# HC32K118 register map
File version: 1.0
CPU: CM0+ r0p1, little endian, no MPU, no FPU, 2 interrupt priority bits
Registers are 32-bit, read-write, reset 0x0 unless marked. A register's access mark holds for its fields unless they carry their own. Offsets are from the block's base; [hi:lo] are bit positions; {n}, {i} and the like mark numbered series; 'fields as' and 'values as' point back to an identical list.

## CMU
Base 0x40014400
0x00 PERICKSEL 8-bit
  [2:0] PERICKSEL
0x04 XTALSTDSR 8-bit
  [0] XTALSTDF
0x08 SCKDIVR 8-bit
  [2:0] SCKDIV
0x0C CKSWR 8-bit
  [1:0] CKSW
0x10 XTALCR 8-bit reset 0x1
  [0] XTALSTP
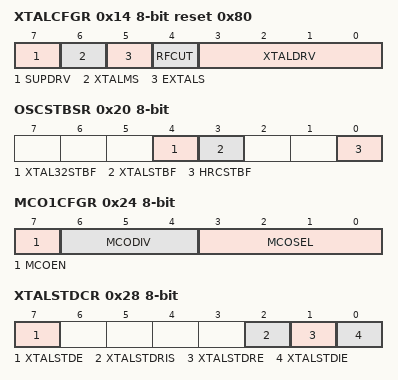
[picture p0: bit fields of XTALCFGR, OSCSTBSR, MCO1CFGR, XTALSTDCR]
0x14 XTALCFGR 8-bit reset 0x80
  [7] SUPDRV, [6] XTALMS, [5] EXTALS, [4] RFCUT, [3:0] XTALDRV
0x15 XTALSTBCR 8-bit
  [2:0] XTALSTB
0x18 HRCCR 8-bit
  [0] HRCSTP
0x20 OSCSTBSR 8-bit ro
  [4] XTAL32STBF, [3] XTALSTBF, [0] HRCSTBF
0x24 MCO1CFGR 8-bit
  [7] MCOEN, [6:4] MCODIV, [3:0] MCOSEL
0x28 XTALSTDCR 8-bit
  [7] XTALSTDE, [2] XTALSTDRIS, [1] XTALSTDRE, [0] XTALSTDIE
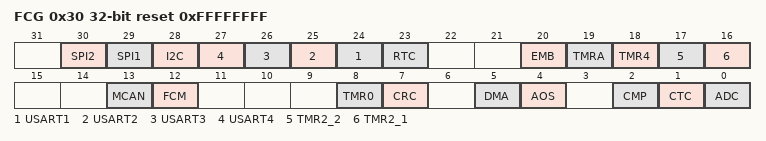
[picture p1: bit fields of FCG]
0x30 FCG reset 0xFFFFFFFF
  [30] SPI2, [29] SPI1, [28] I2C, [n+23] USART{n} (n=1..4), [23] RTC, [20] EMB, [19] TMRA, [18] TMR4, [17] TMR2_2, [16] TMR2_1, [13] MCAN, [12] FCM, [8] TMR0, [7] CRC, [5] DMA, [4] AOS, [2] CMP, [1] CTC, [0] ADC
0x34 XTAL32CR 8-bit reset 0x1
  [0] XTAL32STP
0x38 XTAL32CFGR 8-bit
  [0] XTAL32DRV
0x39 XTAL32NFR 8-bit
  [1:0] XTAL32NF
0x3C LRCCR 8-bit
  [0] LRCSTP
0x40 CANCKCFGR 8-bit
  [0] CANCKS

## CRC
Base 0x40015400
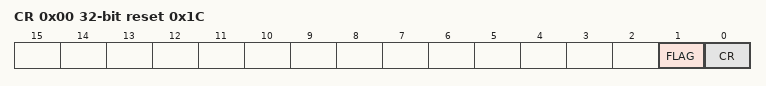
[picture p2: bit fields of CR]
0x00 CR reset 0x1C
  [1] FLAG, [0] CR
0x04 RESLT reset 0x7800
{0x80+4i} DAT{i} (i=0..31)

## CTC
Base 0x40000000
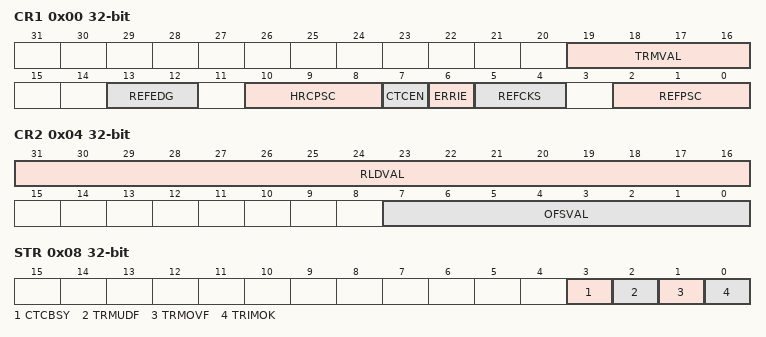
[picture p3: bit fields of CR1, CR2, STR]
0x00 CR1
  [19:16] TRMVAL, [13:12] REFEDG, [10:8] HRCPSC, [7] CTCEN, [6] ERRIE, [5:4] REFCKS, [2:0] REFPSC
0x04 CR2
  [31:16] RLDVAL, [7:0] OFSVAL
0x08 STR ro
  [3] CTCBSY, [2] TRMUDF, [1] TRMOVF, [0] TRIMOK
0x0C CNT 16-bit ro

## DBGC
Base 0x40015000
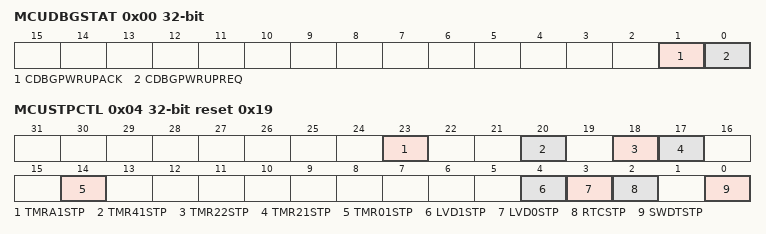
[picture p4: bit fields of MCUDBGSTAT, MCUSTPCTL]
0x00 MCUDBGSTAT
  [1] CDBGPWRUPACK, [0] CDBGPWRUPREQ
0x04 MCUSTPCTL reset 0x19
  [23] TMRA1STP, [20] TMR41STP, [18] TMR22STP, [17] TMR21STP, [14] TMR01STP, [4] LVD1STP, [3] LVD0STP, [2] RTCSTP, [0] SWDTSTP

## DBGC_T
Base 0xE0042000
{0x0+4i} AUTHID{i} (i=0..2)
0x0C CHIPID ro reset 0x58480118
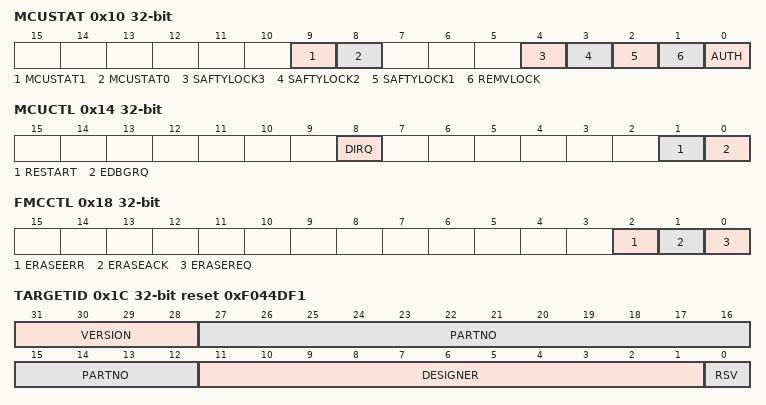
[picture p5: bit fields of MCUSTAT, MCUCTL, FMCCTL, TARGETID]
0x10 MCUSTAT
  [9] MCUSTAT1, [8] MCUSTAT0, [4] SAFTYLOCK3, [3] SAFTYLOCK2, [2] SAFTYLOCK1, [1] REMVLOCK, [0] AUTH
0x14 MCUCTL
  [8] DIRQ, [1] RESTART, [0] EDBGRQ
0x18 FMCCTL
  [2] ERASEERR, [1] ERASEACK, [0] ERASEREQ
0x1C TARGETID ro reset 0xF044DF1
  [31:28] VERSION, [27:12] PARTNO, [11:1] DESIGNER, [0] RSV

## DMA
Base 0x40013000
0x00 EN
  [0] EN
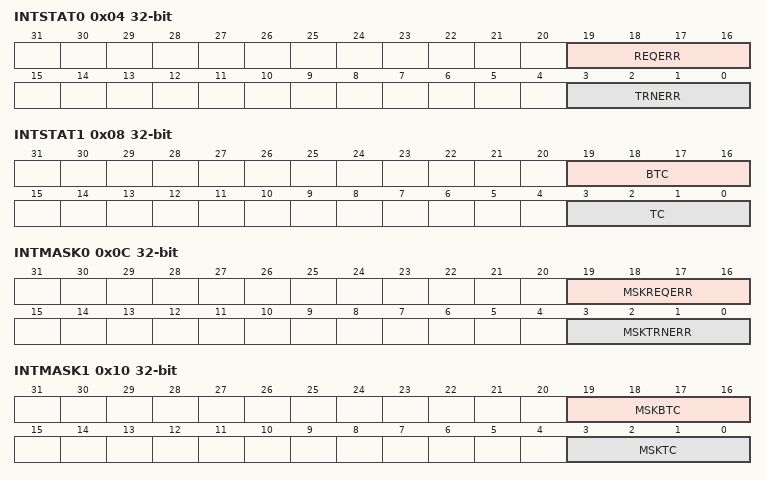
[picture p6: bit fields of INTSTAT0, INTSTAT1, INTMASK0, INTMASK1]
0x04 INTSTAT0 ro
  [19:16] REQERR, [3:0] TRNERR
0x08 INTSTAT1 ro
  [19:16] BTC, [3:0] TC
0x0C INTMASK0
  [19:16] MSKREQERR, [3:0] MSKTRNERR
0x10 INTMASK1
  [19:16] MSKBTC, [3:0] MSKTC
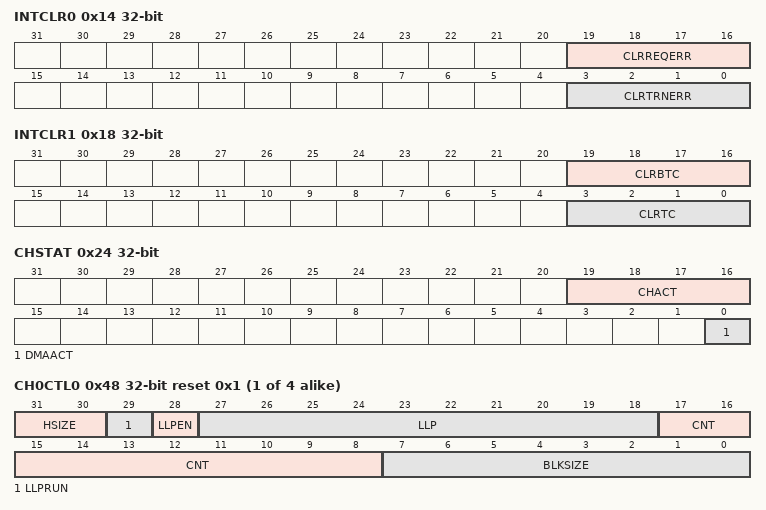
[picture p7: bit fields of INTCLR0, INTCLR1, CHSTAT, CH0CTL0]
0x14 INTCLR0 wo
  [19:16] CLRREQERR, [3:0] CLRTRNERR
0x18 INTCLR1 wo
  [19:16] CLRBTC, [3:0] CLRTC
0x1C CHEN
  [3:0] CHEN
0x24 CHSTAT ro
  [19:16] CHACT, [0] DMAACT
0x30 BASE1_LLP reset 0x20000000
  [31:14] LLP
0x34 BASE2_LLP
  [31:14] LLP
0x38 CHENCLR wo
  [3:0] CHENCLR
{0x40+0x40*i} SAR{i} (i=0..3)
{0x44+0x40*i} DAR{i} (i=0..3)
{0x48+0x40*i} CH{i}CTL0 reset 0x1 (i=0..3)
  [31:30] HSIZE, [29] LLPRUN, [28] LLPEN, [27:18] LLP, [17:8] CNT, [7:0] BLKSIZE
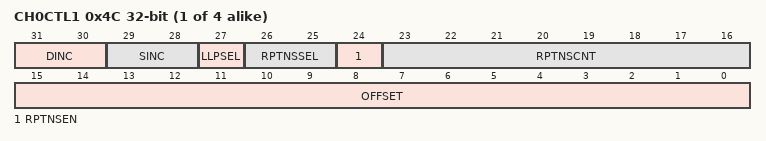
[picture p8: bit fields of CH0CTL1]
{0x4C+0x40*i} CH{i}CTL1 (i=0..3)
  [31:30] DINC, [29:28] SINC, [27] LLPSEL, [26:25] RPTNSSEL, [24] RPTNSEN, [23:16] RPTNSCNT, [15:0] OFFSET

## EFM
Base 0x40000400
0x00 DFAPRT
  [15:0] FAPRT
0x04 DKEY1
0x08 DKEY2
0x14 DFSTP
  [0] FSTP
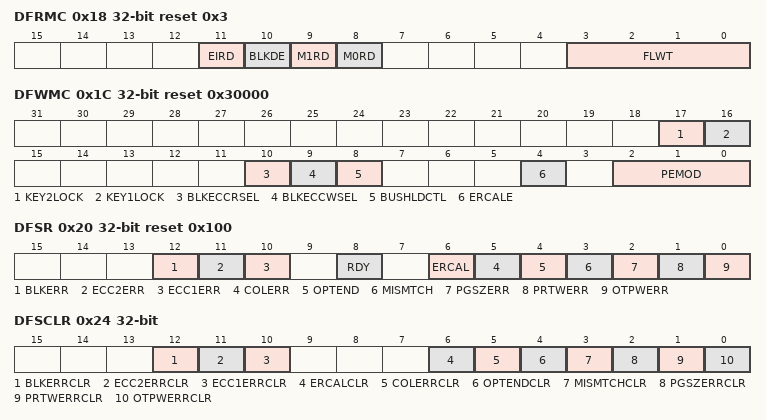
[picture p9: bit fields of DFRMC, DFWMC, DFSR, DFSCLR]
0x18 DFRMC reset 0x3
  [11] EIRD, [10] BLKDE, [9] M1RD, [8] M0RD, [3:0] FLWT
0x1C DFWMC reset 0x30000
  [17] KEY2LOCK, [16] KEY1LOCK, [10] BLKECCRSEL, [9] BLKECCWSEL, [8] BUSHLDCTL, [4] ERCALE, [2:0] PEMOD
0x20 DFSR ro reset 0x100
  [12] BLKERR, [11] ECC2ERR, [10] ECC1ERR, [8] RDY, [6] ERCAL, [5] COLERR, [4] OPTEND, [3] MISMTCH, [2] PGSZERR, [1] PRTWERR, [0] OTPWERR
0x24 DFSCLR
  [12] BLKERRCLR, [11] ECC2ERRCLR, [10] ECC1ERRCLR, [6] ERCALCLR, [5] COLERRCLR, [4] OPTENDCLR, [3] MISMTCHCLR, [2] PGSZERRCLR, [1] PRTWERRCLR, [0] OTPWERRCLR
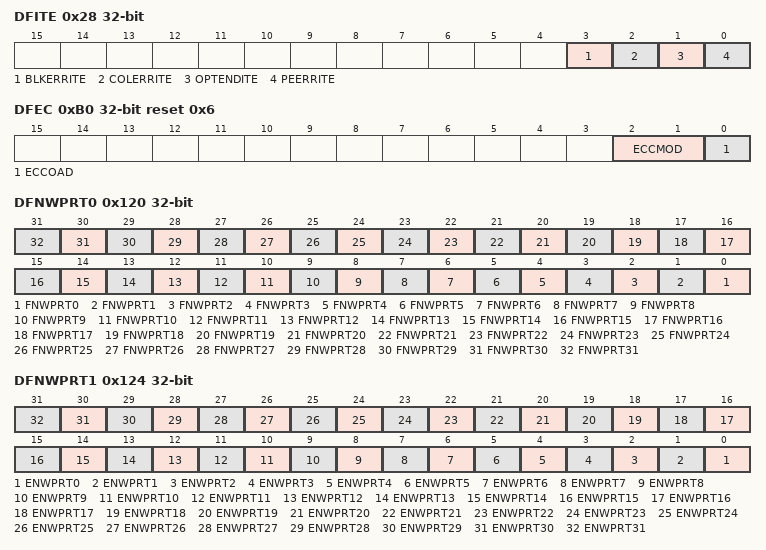
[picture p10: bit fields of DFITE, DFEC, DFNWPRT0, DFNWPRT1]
0x28 DFITE
  [3] BLKERRITE, [2] COLERRITE, [1] OPTENDITE, [0] PEERRITE
0xB0 DFEC reset 0x6
  [2:1] ECCMOD, [0] ECCOAD
0xB4 DFECERA ro reset 0x40000000
0xB8 DERI0
0xC0 DERI2
  [6:0] ERI2
0x120 DFNWPRT0
  [n] FNWPRT{n} (n=0..31)
0x124 DFNWPRT1
  [n] ENWPRT{n} (n=0..31)
0x400 FAPRT
  [15:0] FAPRT
0x404 KEY1
0x408 KEY2
0x414 FSTP
  [0] FSTP
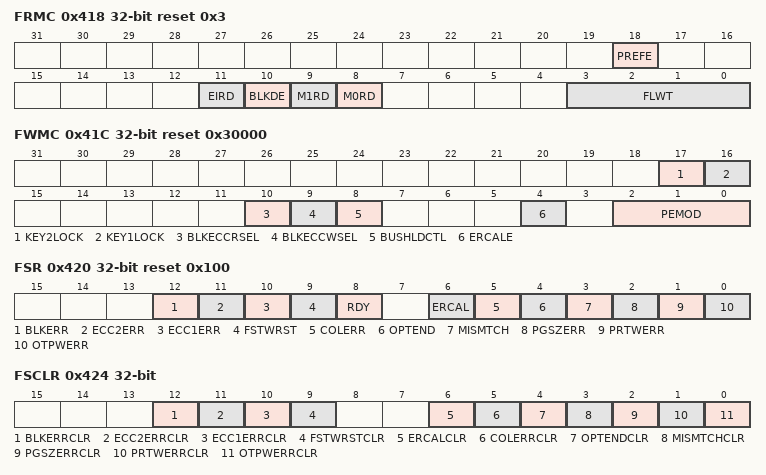
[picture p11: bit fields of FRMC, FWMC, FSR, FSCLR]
0x418 FRMC reset 0x3
  [18] PREFE, [11] EIRD, [10] BLKDE, [9] M1RD, [8] M0RD, [3:0] FLWT
0x41C FWMC reset 0x30000
  fields as DFWMC
0x420 FSR ro reset 0x100
  [12] BLKERR, [11] ECC2ERR, [10] ECC1ERR, [9] FSTWRST, [8] RDY, [6] ERCAL, [5] COLERR, [4] OPTEND, [3] MISMTCH, [2] PGSZERR, [1] PRTWERR, [0] OTPWERR
0x424 FSCLR
  [12] BLKERRCLR, [11] ECC2ERRCLR, [10] ECC1ERRCLR, [9] FSTWRSTCLR, [6] ERCALCLR, [5] COLERRCLR, [4] OPTENDCLR, [3] MISMTCHCLR, [2] PGSZERRCLR, [1] PRTWERRCLR, [0] OTPWERRCLR
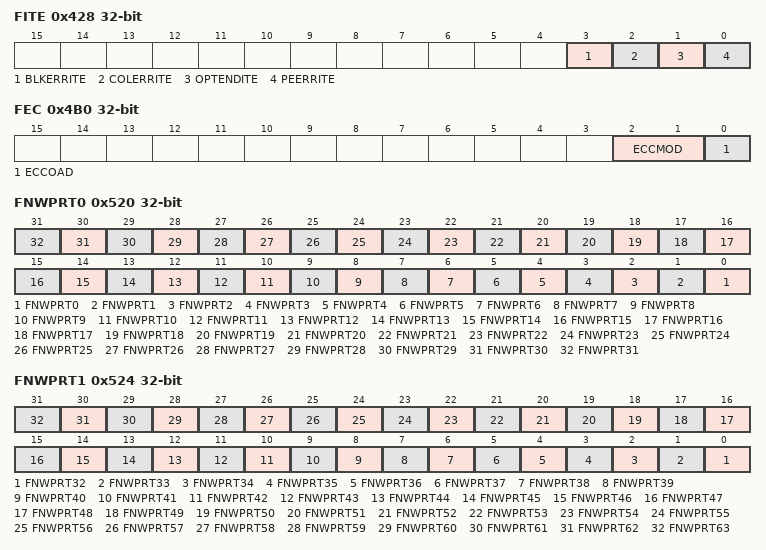
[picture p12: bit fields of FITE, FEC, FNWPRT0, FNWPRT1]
0x428 FITE
  [3] BLKERRITE, [2] COLERRITE, [1] OPTENDITE, [0] PEERRITE
0x42C FSWP ro
  [0] FSWP
0x440 CHIPID ro reset 0x58480118
{0x450+4i} UQID{i} ro (i=0..2)
0x4B0 FEC
  [2:1] ECCMOD, [0] ECCOAD
0x4B4 FECERA ro
0x4B8 ERI0
0x4BC ERI1
0x4C0 ERI2
  [7:0] ERI2
0x520 FNWPRT0
  [n] FNWPRT{n} (n=0..31)
0x524 FNWPRT1
  [n-32] FNWPRT{n} (n=32..63)
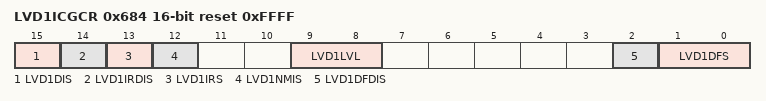
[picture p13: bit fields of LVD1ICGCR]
0x684 LVD1ICGCR 16-bit reset 0xFFFF
  [15] LVD1DIS, [14] LVD1IRDIS, [13] LVD1IRS, [12] LVD1NMIS, [9:8] LVD1LVL, [2] LVD1DFDIS, [1:0] LVD1DFS
0x686 HRCCFGR 8-bit
  [3:0] HRCFREQS
